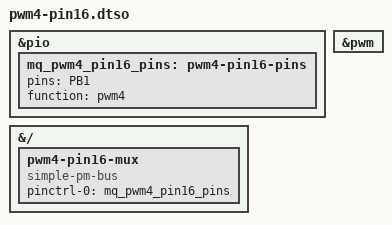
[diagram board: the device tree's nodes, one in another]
// SPDX-License-Identifier: (GPL-2.0+ OR MIT)
// Mangue OS header overlay pwm4-pin16 — GENERATED by tools/gen_overlays.py,
// edit overlays/header_table.py instead.
//
// pin port  role
//  16 PB1   pwm4
// device: /sys/class/pwm/pwmchip0 channel 4

/dts-v1/;
/plugin/;

#include <dt-bindings/gpio/gpio.h>
#include <dt-bindings/interrupt-controller/irq.h>
#include <dt-bindings/input/linux-event-codes.h>

&pio {
	mq_pwm4_pin16_pins: pwm4-pin16-pins {
		pins = "PB1";
		function = "pwm4";
	};
};

&pwm {
	status = "okay";
};

&{/} {
	pwm4-pin16-mux {
		compatible = "simple-pm-bus";
		pinctrl-names = "default";
		pinctrl-0 = <&mq_pwm4_pin16_pins>;
	};
};
